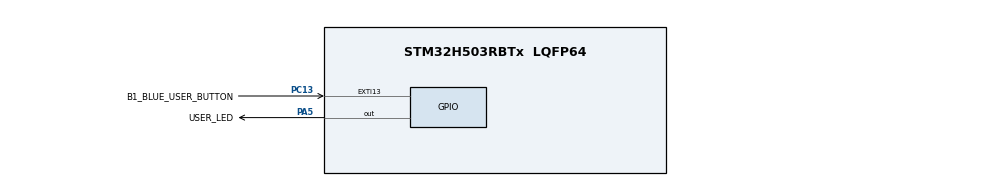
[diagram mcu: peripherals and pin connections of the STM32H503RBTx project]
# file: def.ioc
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BOOTPATH.BootPathName=LEGACY
BOOTPATH.UserSelectedBootPath=LEGACY
Mcu.Family=STM32H5
Mcu.Name=STM32H503RBTx
Mcu.Package=LQFP64
NVIC.PriorityGroup=NVIC_PRIORITYGROUP_4
PA3.GPIO_Label=T_VCP_RX
PA3.Signal=USART3_RX
PA4.GPIO_Label=T_VCP_TX
PA4.Signal=USART3_TX
PA5.GPIO_Label=USER_LED
PA5.Signal=GPIO_Output
PC13.GPIO_Label=B1_BLUE_USER_BUTTON
PC13.Signal=GPXTI13
ProjectManager.HeapSize=0x200
ProjectManager.StackSize=0x400
ProjectManager.TargetToolchain=STM32CubeIDE
RCC.ADCFreq_Value=64000000
RCC.AHBFreq_Value=64000000
RCC.APB1Freq_Value=64000000
RCC.APB1TimFreq_Value=64000000
RCC.APB2Freq_Value=64000000
RCC.APB2TimFreq_Value=64000000
RCC.APB3Freq_Value=64000000
RCC.CSI_VALUE=4000000
RCC.CortexFreq_Value=64000000
RCC.EPOD_VALUE=4000000
RCC.HCLKFreq_Value=64000000
RCC.HSE_VALUE=24000000
RCC.HSI48_VALUE=48000000
RCC.HSIDiv=RCC_HSI_DIV1
RCC.HSI_VALUE=64000000
RCC.LSE_VALUE=32768
RCC.LSIRC_VALUE=32000
RCC.PLLN=32
RCC.SYSCLKFreq_VALUE=64000000
RCC.USBFreq_Value=48000000
RCC.VCOOutputFreq_Value=128000000
STMicroelectronics.X-CUBE-FREERTOS.1.3.0.RTOS2CcCMSISJjRTOS2JjCore=TZIiNonIiSupported
STMicroelectronics.X-CUBE-FREERTOS.1.3.0.RTOS2CcCMSISJjRTOS2JjHeap=HeapIi1
STMicroelectronics.X-CUBE-FREERTOS.1.3.0.configGENERATE_RUN_TIME_STATS=1
STMicroelectronics.X-CUBE-FREERTOS.1.3.0.configUSE_STATS_FORMATTING_FUNCTIONS=1
VP_BOOTPATH_VS_BOOTPATH.Mode=BP_Activate
VP_CORTEX_M33_NS_VS_Hclk.Mode=Hclk_Mode
VP_MEMORYMAP_VS_MEMORYMAP.Mode=CurAppReg
VP_PWR_VS_DBSignals.Mode=DisableDeadBatterySignals
VP_PWR_VS_LPOM.Mode=PowerOptimisation
VP_PWR_VS_SECSignals.Mode=Security/Privilege
VP_STMicroelectronics.X-CUBE-FREERTOS_VS_CMSISJjRTOS2_10.6.2_1.3.0.Mode=CMSISJjRTOS2
board=NUCLEO-H503RB

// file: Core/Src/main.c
/* USER CODE BEGIN Header */
/**
  ******************************************************************************
  * @file           : main.c
  * @brief          : Main program body
  ******************************************************************************
  * @attention
  *
  * Copyright (c) 2025 STMicroelectronics.
  * All rights reserved.
  *
  * This software is licensed under terms that can be found in the LICENSE file
  * in the root directory of this software component.
  * If no LICENSE file comes with this software, it is provided AS-IS.
  *
  ******************************************************************************
  */
/* USER CODE END Header */
#include "main.h"
//#include "cmsis_os2.h"
#include "FreeRTOS.h"
#include "task.h"

void SystemClock_Config(void);
//void MX_FREERTOS_Init(void);
static void MX_GPIO_Init(void);
static void MX_ICACHE_Init(void);

int main(void)
{

  /* MCU Configuration--------------------------------------------------------*/

  /* Reset of all peripherals, Initializes the Flash interface and the Systick. */
  HAL_Init();

  /* Configure the system clock */
  SystemClock_Config();

  /* Initialize all configured peripherals */
  MX_GPIO_Init();
  MX_ICACHE_Init();

  /* Init scheduler */
  //osKernelInitialize();

  /* Call init function for freertos objects (in app_freertos.c) */
  //MX_FREERTOS_Init();

  /* Start scheduler */
  //osKernelStart();
  vTaskStartScheduler();

  /* We should never get here as control is now taken by the scheduler */

  /* Infinite loop */
  while (1)
  {

  }
}

void SystemClock_Config(void)
{
  RCC_OscInitTypeDef RCC_OscInitStruct = {0};
  RCC_ClkInitTypeDef RCC_ClkInitStruct = {0};

  /** Configure the main internal regulator output voltage
  */
  __HAL_PWR_VOLTAGESCALING_CONFIG(PWR_REGULATOR_VOLTAGE_SCALE3);

  while(!__HAL_PWR_GET_FLAG(PWR_FLAG_VOSRDY)) {}

  /** Initializes the RCC Oscillators according to the specified parameters
  * in the RCC_OscInitTypeDef structure.
  */
  RCC_OscInitStruct.OscillatorType = RCC_OSCILLATORTYPE_HSI;
  RCC_OscInitStruct.HSIState = RCC_HSI_ON;
  RCC_OscInitStruct.HSIDiv = RCC_HSI_DIV2;
  RCC_OscInitStruct.HSICalibrationValue = RCC_HSICALIBRATION_DEFAULT;
  RCC_OscInitStruct.PLL.PLLState = RCC_PLL_NONE;
  if (HAL_RCC_OscConfig(&RCC_OscInitStruct) != HAL_OK)
  {
    Error_Handler();
  }

  /** Initializes the CPU, AHB and APB buses clocks
  */
  RCC_ClkInitStruct.ClockType = RCC_CLOCKTYPE_HCLK|RCC_CLOCKTYPE_SYSCLK
                              |RCC_CLOCKTYPE_PCLK1|RCC_CLOCKTYPE_PCLK2
                              |RCC_CLOCKTYPE_PCLK3;
  RCC_ClkInitStruct.SYSCLKSource = RCC_SYSCLKSOURCE_HSI;
  RCC_ClkInitStruct.AHBCLKDivider = RCC_SYSCLK_DIV1;
  RCC_ClkInitStruct.APB1CLKDivider = RCC_HCLK_DIV1;
  RCC_ClkInitStruct.APB2CLKDivider = RCC_HCLK_DIV1;
  RCC_ClkInitStruct.APB3CLKDivider = RCC_HCLK_DIV1;

  if (HAL_RCC_ClockConfig(&RCC_ClkInitStruct, FLASH_LATENCY_1) != HAL_OK)
  {
    Error_Handler();
  }

  /** Configure the programming delay
  */
  __HAL_FLASH_SET_PROGRAM_DELAY(FLASH_PROGRAMMING_DELAY_0);
}

static void MX_ICACHE_Init(void)
{

  /** Enable instruction cache in 1-way (direct mapped cache)
  */
  if (HAL_ICACHE_ConfigAssociativityMode(ICACHE_1WAY) != HAL_OK)
  {
    Error_Handler();
  }
  if (HAL_ICACHE_Enable() != HAL_OK)
  {
    Error_Handler();
  }

}

static void MX_GPIO_Init(void)
{

  /* GPIO Ports Clock Enable */
  __HAL_RCC_GPIOA_CLK_ENABLE();
  __HAL_RCC_GPIOB_CLK_ENABLE();

}

/* USER CODE BEGIN 4 */

int __io_putchar(int ch)
{
    ITM_SendChar(ch);
    //HAL_UART_Transmit(&huart3, (uint8_t *)&ch, 1, 0xFF); unkomment, if want send on uart also
    return (ch);
}

/* USER CODE END 4 */

void HAL_TIM_PeriodElapsedCallback(TIM_HandleTypeDef *htim)
{
  if (htim->Instance == TIM1) {
    HAL_IncTick();
  }
}

void Error_Handler(void)
{
  __disable_irq();
  while (1)
  {
  }
}

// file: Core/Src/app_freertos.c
/* USER CODE BEGIN Header */
/**
  ******************************************************************************
  * File Name          : app_freertos.c
  * Description        : FreeRTOS applicative file
  ******************************************************************************
  * @attention
  *
  * Copyright (c) 2025 STMicroelectronics.
  * All rights reserved.
  *
  * This software is licensed under terms that can be found in the LICENSE file
  * in the root directory of this software component.
  * If no LICENSE file comes with this software, it is provided AS-IS.
  *
  ******************************************************************************
  */
/* USER CODE END Header */

#include "app_freertos.h"

/* Definitions for defaultTask */
osThreadId_t defaultTaskHandle;
const osThreadAttr_t defaultTask_attributes = {
  .name = "defaultTask",
  .priority = (osPriority_t) osPriorityNormal,
  .stack_size = 128 * 4
};

/* USER CODE BEGIN 1 */
/* Functions needed when configGENERATE_RUN_TIME_STATS is on */
__weak void configureTimerForRunTimeStats(void)
{

}

__weak unsigned long getRunTimeCounterValue(void)
{
return 0;
}
/* USER CODE END 1 */

void MX_FREERTOS_Init(void) {

  /* creation of defaultTask */
  defaultTaskHandle = osThreadNew(StartDefaultTask, NULL, &defaultTask_attributes);

}
void StartDefaultTask(void *argument)
{
  for(;;)
  {
    osDelay(1);
  }
}
